VERSION ""

NS_ :

BS_:

BU_: Car1516_ATCC_Rear

BO_ 53 Car12_ATCC_Rear_5: 8 Car1516_ATCC_Rear
 SG_ Water_Outlet_Temp : 16|16@1- (0.1,0) [-3276.8|3276.7] "°C" Vector__XXX
 SG_ Water_Inlet_Temp : 0|16@1- (0.1,0) [-3276.8|3276.7] "°C" Vector__XXX

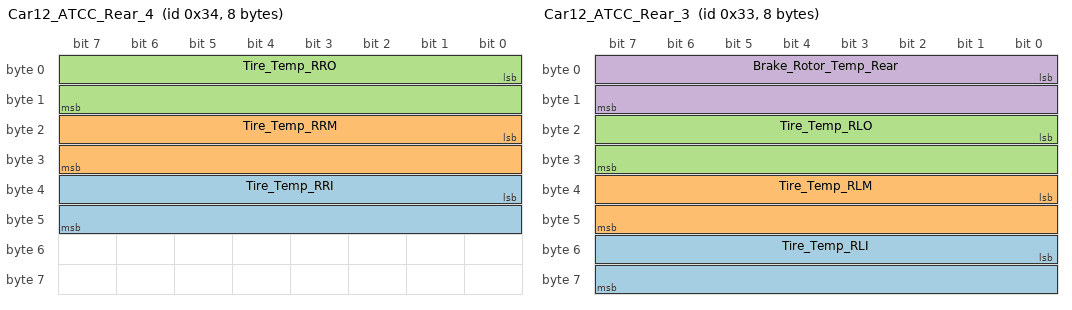
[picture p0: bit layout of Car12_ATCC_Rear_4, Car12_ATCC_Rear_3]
BO_ 52 Car12_ATCC_Rear_4: 8 Car1516_ATCC_Rear
 SG_ Tire_Temp_RRI : 32|16@1- (0.18,32) [-5866.24|5930.06] "°F" Vector__XXX
 SG_ Tire_Temp_RRM : 16|16@1- (0.18,32) [-5866.24|5930.06] "°F" Vector__XXX
 SG_ Tire_Temp_RRO : 0|16@1- (0.18,32) [-5866.24|5930.06] "°F" Vector__XXX

BO_ 51 Car12_ATCC_Rear_3: 8 Car1516_ATCC_Rear
 SG_ Tire_Temp_RLI : 48|16@1- (0.18,32) [-5866.24|5930.06] "°F" Vector__XXX
 SG_ Tire_Temp_RLM : 32|16@1- (0.18,32) [-5866.24|5930.06] "°F" Vector__XXX
 SG_ Tire_Temp_RLO : 16|16@1- (0.18,32) [-5866.24|5930.06] "°F" Vector__XXX
 SG_ Brake_Rotor_Temp_Rear : 0|16@1- (0.1,0) [-3276.8|3276.7] "°C" Vector__XXX

BO_ 50 Car12_ATCC_Rear_2: 8 Car1516_ATCC_Rear
 SG_ Brake_Press_RR : 0|16@1- (0.1,0) [-3276.8|3276.7] "psi" Vector__XXX

BO_ 49 Car12_ATCC_Rear_1: 8 Car1516_ATCC_Rear

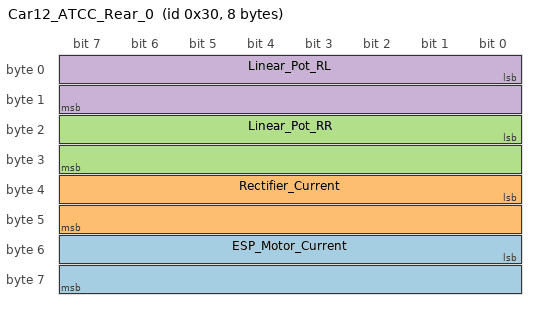
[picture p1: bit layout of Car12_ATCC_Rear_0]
BO_ 48 Car12_ATCC_Rear_0: 8 Car1516_ATCC_Rear
 SG_ ESP_Motor_Current : 48|16@1- (0.0125,0) [-409.6|409.5875] "A" Vector__XXX
 SG_ Rectifier_Current : 32|16@1- (0.0125,0) [-409.6|409.5875] "A" Vector__XXX
 SG_ Linear_Pot_RR : 16|16@1- (-0.01,75) [0|75] "cm" Vector__XXX
 SG_ Linear_Pot_RL : 0|16@1- (-0.01,75) [0|75] "cm" Vector__XXX
